VERSION ""

NS_ :

BU_: EBCM EON CAM RADAR PCM EPS VSA SCM BDY XXX EPB

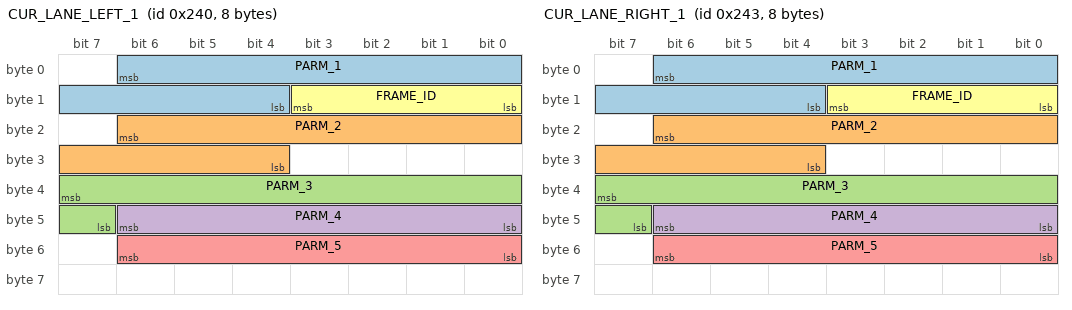
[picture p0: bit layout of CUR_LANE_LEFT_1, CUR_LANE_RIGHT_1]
BO_ 576 CUR_LANE_LEFT_1: 8 XXX
 SG_ PARM_1 : 6|11@0- (1,0) [-1023|1023] "" XXX
 SG_ PARM_2 : 22|11@0- (1,0) [-1023|1023] "" XXX
 SG_ PARM_3 : 39|9@0+ (1,0) [0|511] "" XXX
 SG_ PARM_4 : 46|7@0+ (1,0) [0|127] "" XXX
 SG_ PARM_5 : 54|7@0+ (1,0) [0|127] "" XXX
 SG_ FRAME_ID : 11|4@0+ (1,0) [0|15] "" XXX

BO_ 577 CUR_LANE_LEFT_2: 8 XXX
 SG_ PARM_6 : 3|8@0+ (1,0) [0|255] "" XXX
 SG_ PARM_7 : 22|11@0- (1,0) [-1023|1023] "" XXX
 SG_ PARM_8 : 24|4@0+ (1,0) [0|15] "" XXX
 SG_ PARM_9 : 38|11@0- (1,0) [-1023|1023] "" XXX
 SG_ PARM_10 : 54|7@0- (1,0) [-63|63] "" XXX
 SG_ FRAME_ID : 7|4@0+ (1,0) [0|15] "" XXX
 SG_ DASHED_LINE : 14|1@0+ (1,0) [0|1] "" XXX
 SG_ SOLID_LINE : 13|1@0+ (1,0) [0|1] "" XXX

BO_ 579 CUR_LANE_RIGHT_1: 8 XXX
 SG_ PARM_1 : 6|11@0- (1,0) [-1023|1023] "" XXX
 SG_ PARM_2 : 22|11@0- (1,0) [-1023|1023] "" XXX
 SG_ PARM_3 : 39|9@0+ (1,0) [0|511] "" XXX
 SG_ PARM_4 : 46|7@0+ (1,0) [0|127] "" XXX
 SG_ PARM_5 : 54|7@0+ (1,0) [0|127] "" XXX
 SG_ FRAME_ID : 11|4@0+ (1,0) [0|15] "" XXX

BO_ 580 CUR_LANE_RIGHT_2: 8 XXX
 SG_ PARM_6 : 3|8@0+ (1,0) [0|255] "" XXX
 SG_ PARM_7 : 22|11@0- (1,0) [-1023|1023] "" XXX
 SG_ PARM_8 : 24|4@0+ (1,0) [0|15] "" XXX
 SG_ PARM_9 : 38|11@0- (1,0) [-1023|1023] "" XXX
 SG_ PARM_10 : 54|7@0- (1,0) [-63|63] "" XXX
 SG_ FRAME_ID : 7|4@0+ (1,0) [0|15] "" XXX
 SG_ DASHED_LINE : 14|1@0+ (1,0) [0|1] "" XXX
 SG_ SOLID_LINE : 13|1@0+ (1,0) [0|1] "" XXX

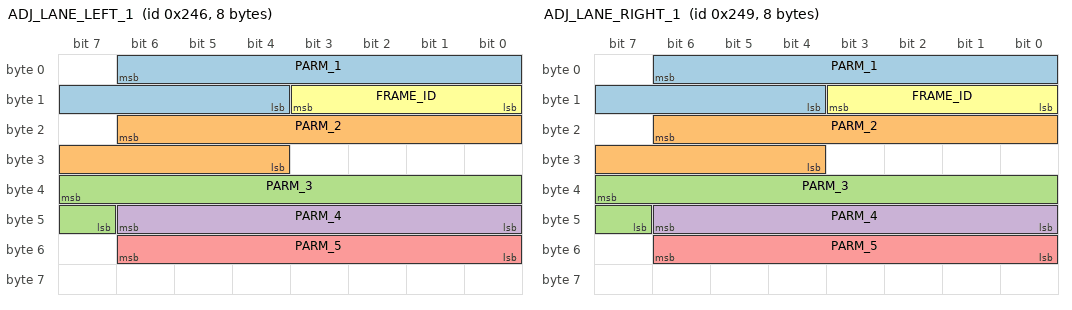
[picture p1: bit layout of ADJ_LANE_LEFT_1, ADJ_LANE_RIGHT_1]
BO_ 582 ADJ_LANE_LEFT_1: 8 XXX
 SG_ PARM_1 : 6|11@0- (1,0) [-1023|1023] "" XXX
 SG_ PARM_2 : 22|11@0- (1,0) [-1023|1023] "" XXX
 SG_ PARM_3 : 39|9@0+ (1,0) [0|511] "" XXX
 SG_ PARM_4 : 46|7@0+ (1,0) [0|127] "" XXX
 SG_ PARM_5 : 54|7@0+ (1,0) [0|127] "" XXX
 SG_ FRAME_ID : 11|4@0+ (1,0) [0|15] "" XXX

BO_ 583 ADJ_LANE_LEFT_2: 8 XXX
 SG_ PARM_6 : 3|8@0+ (1,0) [0|255] "" XXX
 SG_ PARM_7 : 22|11@0- (1,0) [-1023|1023] "" XXX
 SG_ PARM_8 : 24|4@0+ (1,0) [0|15] "" XXX
 SG_ PARM_9 : 38|11@0- (1,0) [-1023|1023] "" XXX
 SG_ PARM_10 : 54|7@0- (1,0) [-63|63] "" XXX
 SG_ FRAME_ID : 7|4@0+ (1,0) [0|15] "" XXX
 SG_ DASHED_LINE : 14|1@0+ (1,0) [0|1] "" XXX
 SG_ SOLID_LINE : 13|1@0+ (1,0) [0|1] "" XXX

BO_ 585 ADJ_LANE_RIGHT_1: 8 XXX
 SG_ PARM_1 : 6|11@0- (1,0) [-1023|1023] "" XXX
 SG_ PARM_2 : 22|11@0- (1,0) [-1023|1023] "" XXX
 SG_ PARM_3 : 39|9@0+ (1,0) [0|511] "" XXX
 SG_ PARM_4 : 46|7@0+ (1,0) [0|127] "" XXX
 SG_ PARM_5 : 54|7@0+ (1,0) [0|127] "" XXX
 SG_ FRAME_ID : 11|4@0+ (1,0) [0|15] "" XXX

BO_ 586 ADJ_LANE_RIGHT_2: 8 XXX
 SG_ PARM_6 : 3|8@0+ (1,0) [0|255] "" XXX
 SG_ PARM_7 : 22|11@0- (1,0) [-1023|1023] "" XXX
 SG_ PARM_8 : 24|4@0+ (1,0) [0|15] "" XXX
 SG_ PARM_9 : 38|11@0- (1,0) [-1023|1023] "" XXX
 SG_ PARM_10 : 54|7@0- (1,0) [-63|63] "" XXX
 SG_ FRAME_ID : 7|4@0+ (1,0) [0|15] "" XXX
 SG_ DASHED_LINE : 14|1@0+ (1,0) [0|1] "" XXX
 SG_ SOLID_LINE : 13|1@0+ (1,0) [0|1] "" XXX
